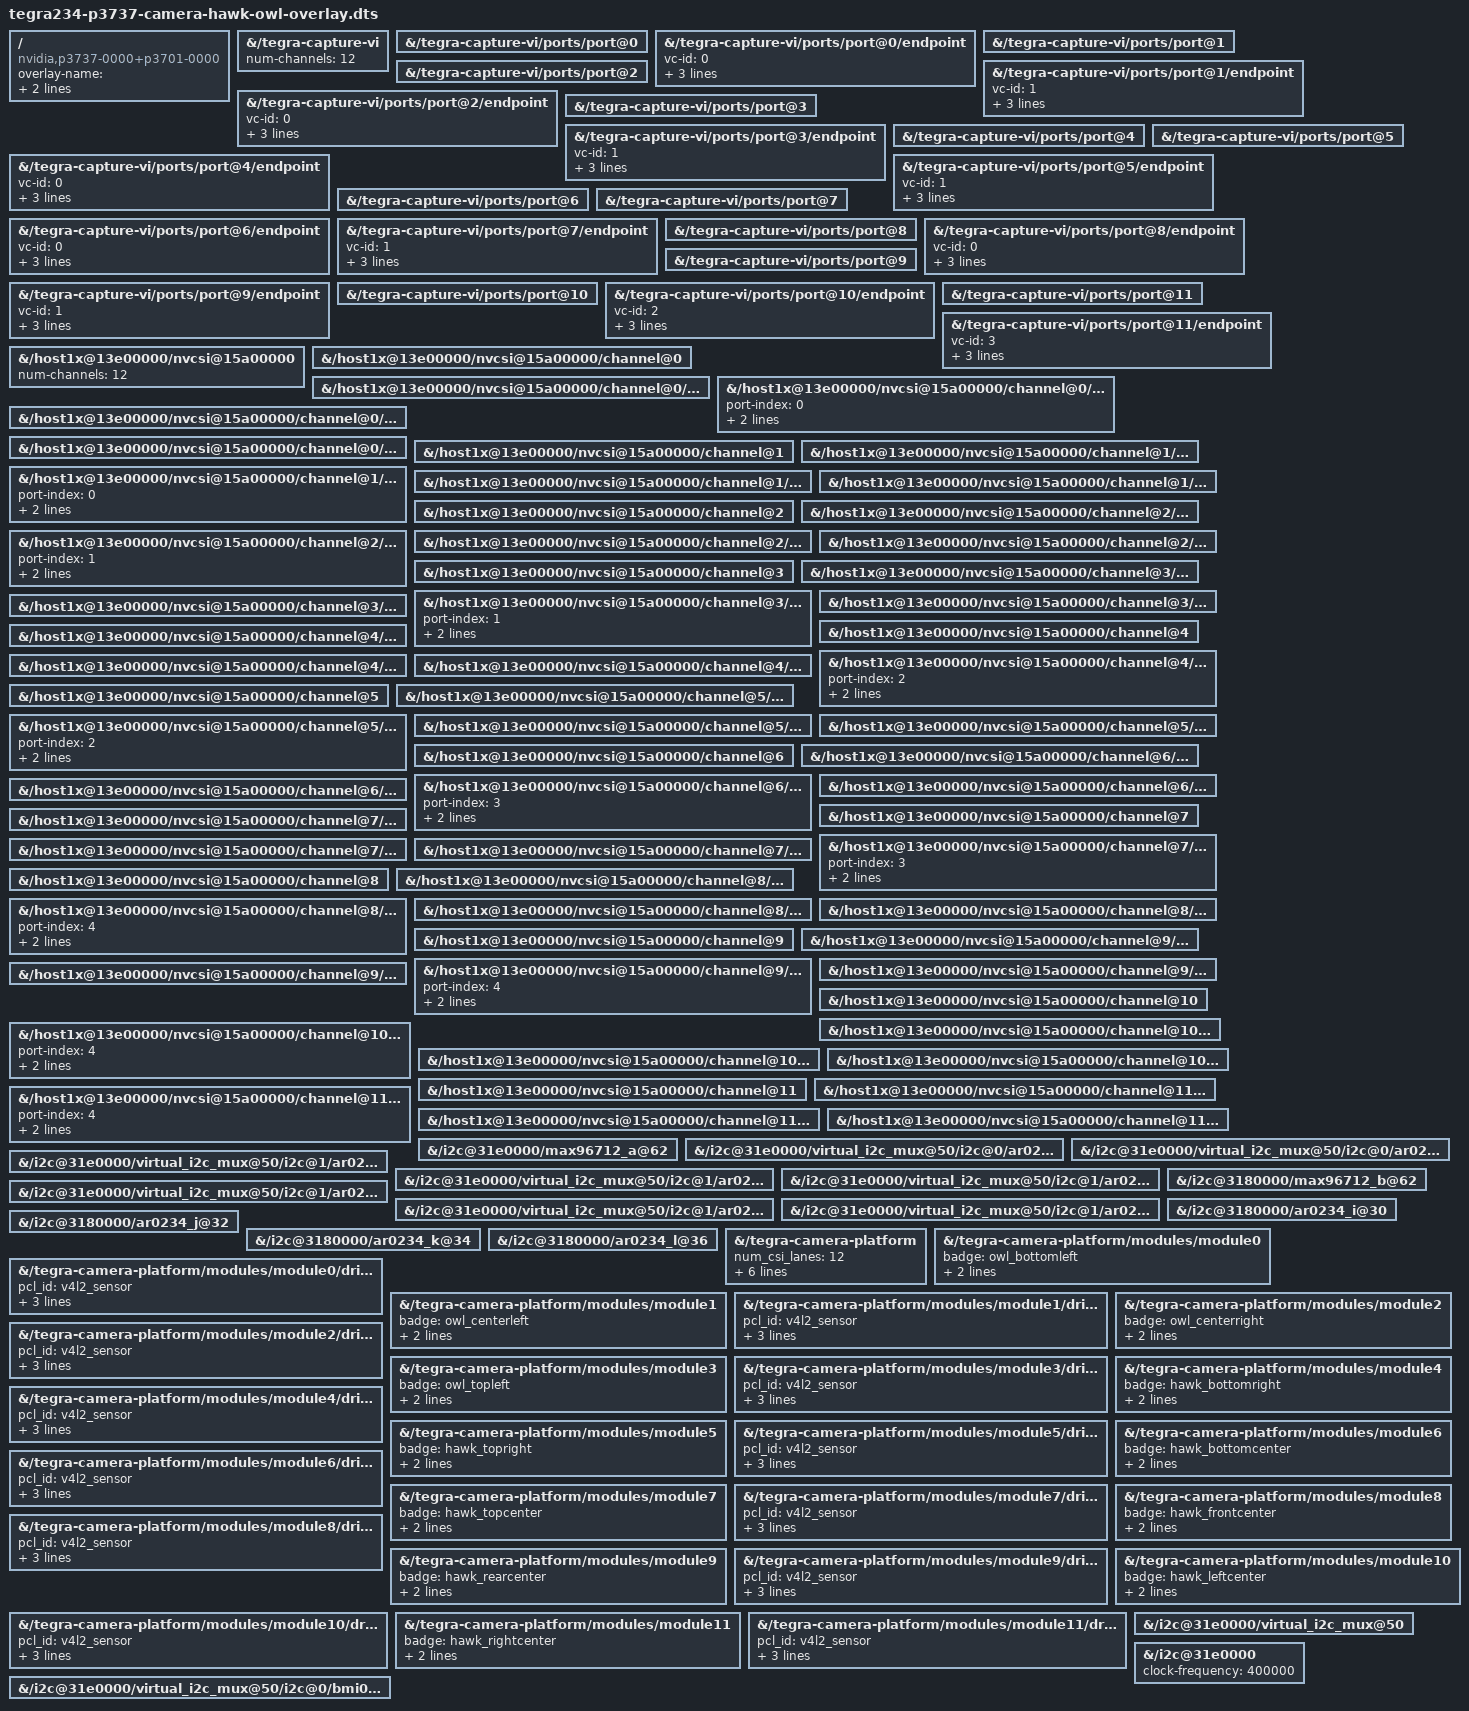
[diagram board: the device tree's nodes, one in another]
// SPDX-License-Identifier: GPL-2.0-only
/*
 * Jetson Device-tree overlay for Camera Hawk & Owl on t23x platforms
 *
 * Copyright (c) 2022-2023 NVIDIA CORPORATION. All rights reserved.
 *
 */


/dts-v1/;
/plugin/;

/ {
	overlay-name = "Jetson Camera Hawk-Owl p3762 module";
	jetson-header-name = "Jetson AGX CSI Connector";
	compatible = "nvidia,p3737-0000+p3701-0000" , "nvidia,p3737-0000+p3701-0004", "nvidia,p3737-0000+p3701-0005", "nvidia,p3737-0000+p3701-0008";

	/* VI number of channels */
	fragment@0 {
		target-path = "/tegra-capture-vi";
		board_config {
			sw-modules = "kernel";
		};
		__overlay__ {
			num-channels=<12>;
		};
	};

	fragment@1 {
		target-path = "/tegra-capture-vi/ports/port@0";
		board_config {
			sw-modules = "kernel";
		};
		__overlay__ {
			status = "okay";
		};
	};
	fragment@2 {
		target-path = "/tegra-capture-vi/ports/port@0/endpoint";
		board_config {
			sw-modules = "kernel";
		};
		__overlay__ {
			status = "okay";
			vc-id = <0>;
			port-index = <0>;
			bus-width = <2>;
			remote-endpoint = <&ar0234_csi_out0>;
		};
	};
	fragment@3 {
		target-path = "/tegra-capture-vi/ports/port@1";
		board_config {
			sw-modules = "kernel";
		};
		__overlay__ {
			status = "okay";
		};
	};
	fragment@4 {
		target-path = "/tegra-capture-vi/ports/port@1/endpoint";
		board_config {
			sw-modules = "kernel";
		};
		__overlay__ {
			status = "okay";
			vc-id = <1>;
			port-index = <0>;
			bus-width = <2>;
			remote-endpoint = <&ar0234_csi_out1>;
		};
	};
	fragment@5 {
		target-path = "/tegra-capture-vi/ports/port@2";
		board_config {
			sw-modules = "kernel";
		};
		__overlay__ {
			status = "okay";
		};
	};
	fragment@6 {
		target-path = "/tegra-capture-vi/ports/port@2/endpoint";
		board_config {
			sw-modules = "kernel";
		};
		__overlay__ {
			status = "okay";
			vc-id = <0>;
			port-index = <1>;
			bus-width = <2>;
			remote-endpoint = <&ar0234_csi_out2>;
		};
	};
	fragment@7 {
		target-path = "/tegra-capture-vi/ports/port@3";
		board_config {
			sw-modules = "kernel";
		};
		__overlay__ {
			status = "okay";
		};
	};
	fragment@8 {
		target-path = "/tegra-capture-vi/ports/port@3/endpoint";
		board_config {
			sw-modules = "kernel";
		};
		__overlay__ {
			status = "okay";
			vc-id = <1>;
			port-index = <1>;
			bus-width = <2>;
			remote-endpoint = <&ar0234_csi_out3>;
		};
	};
	fragment@9 {
		target-path = "/tegra-capture-vi/ports/port@4";
		board_config {
			sw-modules = "kernel";
		};
		__overlay__ {
			status = "okay";
		};
	};
	fragment@10 {
		target-path = "/tegra-capture-vi/ports/port@4/endpoint";
		board_config {
			sw-modules = "kernel";
		};
		__overlay__ {
			status = "okay";
			vc-id = <0>;
			port-index = <2>;
			bus-width = <2>;
			remote-endpoint = <&ar0234_csi_out4>;
		};
	};
	fragment@11 {
		target-path = "/tegra-capture-vi/ports/port@5";
		board_config {
			sw-modules = "kernel";
		};
		__overlay__ {
			status = "okay";
		};
	};
	fragment@12 {
		target-path = "/tegra-capture-vi/ports/port@5/endpoint";
		board_config {
			sw-modules = "kernel";
		};
		__overlay__ {
			status = "okay";
			vc-id = <1>;
			port-index = <2>;
			bus-width = <2>;
			remote-endpoint = <&ar0234_csi_out5>;
		};
	};
	fragment@13 {
		target-path = "/tegra-capture-vi/ports/port@6";
		board_config {
			sw-modules = "kernel";
		};
		__overlay__ {
			status = "okay";
		};
	};
	fragment@14 {
		target-path = "/tegra-capture-vi/ports/port@6/endpoint";
		board_config {
			sw-modules = "kernel";
		};
		__overlay__ {
			status = "okay";
			vc-id = <0>;
			port-index = <3>;
			bus-width = <2>;
			remote-endpoint = <&ar0234_csi_out6>;
		};
	};
	fragment@15 {
		target-path = "/tegra-capture-vi/ports/port@7";
		board_config {
			sw-modules = "kernel";
		};
		__overlay__ {
			status = "okay";
		};
	};
	fragment@16 {
		target-path = "/tegra-capture-vi/ports/port@7/endpoint";
		board_config {
			sw-modules = "kernel";
		};
		__overlay__ {
			status = "okay";
			vc-id = <1>;
			port-index = <3>;
			bus-width = <2>;
			remote-endpoint = <&ar0234_csi_out7>;
		};
	};

	fragment@17 {
		target-path = "/tegra-capture-vi/ports/port@8";
		board_config {
			sw-modules = "kernel";
		};
		__overlay__ {
			status = "okay";
		};
	};
	fragment@18 {
		target-path = "/tegra-capture-vi/ports/port@8/endpoint";
		board_config {
			sw-modules = "kernel";
		};
		__overlay__ {
			status = "okay";
			vc-id = <0>;
			port-index = <4>;
			bus-width = <2>;
			remote-endpoint = <&ar0234_csi_out8>;
		};
	};
	fragment@19 {
		target-path = "/tegra-capture-vi/ports/port@9";
		board_config {
			sw-modules = "kernel";
		};
		__overlay__ {
			status = "okay";
		};
	};
	fragment@20 {
		target-path = "/tegra-capture-vi/ports/port@9/endpoint";
		board_config {
			sw-modules = "kernel";
		};
		__overlay__ {
			status = "okay";
			vc-id = <1>;
			port-index = <4>;
			bus-width = <2>;
			remote-endpoint = <&ar0234_csi_out9>;
		};
	};
	fragment@21 {
		target-path = "/tegra-capture-vi/ports/port@10";
		board_config {
			sw-modules = "kernel";
		};
		__overlay__ {
			status = "okay";
		};
	};
	fragment@22 {
		target-path = "/tegra-capture-vi/ports/port@10/endpoint";
		board_config {
			sw-modules = "kernel";
		};
		__overlay__ {
			status = "okay";
			vc-id = <2>;
			port-index = <4>;
			bus-width = <2>;
			remote-endpoint = <&ar0234_csi_out10>;
		};
	};
	fragment@23 {
		target-path = "/tegra-capture-vi/ports/port@11";
		board_config {
			sw-modules = "kernel";
		};
		__overlay__ {
			status = "okay";
		};
	};
	fragment@24 {
		target-path = "/tegra-capture-vi/ports/port@11/endpoint";
		board_config {
			sw-modules = "kernel";
		};
		__overlay__ {
			status = "okay";
			vc-id = <3>;
			port-index = <4>;
			bus-width = <2>;
			remote-endpoint = <&ar0234_csi_out11>;
		};
	};
	/* HOST1X */
	fragment@25 {
		target-path = "/host1x@13e00000/nvcsi@15a00000";
		board_config {
			sw-modules = "kernel";
		};
		__overlay__ {
			num-channels=<12>;
		};
	};
	fragment@26 {
		target-path = "/host1x@13e00000/nvcsi@15a00000/channel@0";
		board_config {
			sw-modules = "kernel";
		};
		__overlay__ {
			status = "okay";
		};
	};
	fragment@27 {
		target-path = "/host1x@13e00000/nvcsi@15a00000/channel@0/ports/port@0";
		board_config {
			sw-modules = "kernel";
		};
		__overlay__ {
			status = "okay";
		};
	};
	fragment@28 {
		target-path = "/host1x@13e00000/nvcsi@15a00000/channel@0/ports/port@0/endpoint@0";
		board_config {
			sw-modules = "kernel";
		};
		__overlay__ {
			status = "okay";
			port-index = <0>;
			bus-width = <2>;
			remote-endpoint = <&ar0234_ar0234_out0>;
		};
	};
	fragment@29 {
		target-path = "/host1x@13e00000/nvcsi@15a00000/channel@0/ports/port@1";
		board_config {
			sw-modules = "kernel";
		};
		__overlay__ {
			status = "okay";
		};
	};
	fragment@30 {
		target-path = "/host1x@13e00000/nvcsi@15a00000/channel@0/ports/port@1/endpoint@1";
		board_config {
			sw-modules = "kernel";
		};
		__overlay__ {
			status = "okay";
		};
	};
	fragment@31 {
		target-path = "/host1x@13e00000/nvcsi@15a00000/channel@1";
		board_config {
			sw-modules = "kernel";
		};
		__overlay__ {
			status = "okay";
		};
	};
	fragment@32 {
		target-path = "/host1x@13e00000/nvcsi@15a00000/channel@1/ports/port@0";
		board_config {
			sw-modules = "kernel";
		};
		__overlay__ {
			status = "okay";
		};
	};
	fragment@33 {
		target-path = "/host1x@13e00000/nvcsi@15a00000/channel@1/ports/port@0/endpoint@2";
		board_config {
			sw-modules = "kernel";
		};
		__overlay__ {
			status = "okay";
			port-index = <0>;
			bus-width = <2>;
			remote-endpoint = <&ar0234_ar0234_out1>;
		};
	};
	fragment@34 {
		target-path = "/host1x@13e00000/nvcsi@15a00000/channel@1/ports/port@1";
		board_config {
			sw-modules = "kernel";
		};
		__overlay__ {
			status = "okay";
		};
	};
	fragment@35 {
		target-path = "/host1x@13e00000/nvcsi@15a00000/channel@1/ports/port@1/endpoint@3";
		board_config {
			sw-modules = "kernel";
		};
		__overlay__ {
			status = "okay";
		};
	};

	fragment@36 {
		target-path = "/host1x@13e00000/nvcsi@15a00000/channel@2";
		board_config {
			sw-modules = "kernel";
		};
		__overlay__ {
			status = "okay";
		};
	};
	fragment@37 {
		target-path = "/host1x@13e00000/nvcsi@15a00000/channel@2/ports/port@0";
		board_config {
			sw-modules = "kernel";
		};
		__overlay__ {
			status = "okay";
		};
	};
	fragment@38 {
		target-path = "/host1x@13e00000/nvcsi@15a00000/channel@2/ports/port@0/endpoint@4";
		board_config {
			sw-modules = "kernel";
		};
		__overlay__ {
			status = "okay";
			port-index = <1>;
			bus-width = <2>;
			remote-endpoint = <&ar0234_ar0234_out2>;
		};
	};
	fragment@39 {
		target-path = "/host1x@13e00000/nvcsi@15a00000/channel@2/ports/port@1";
		board_config {
			sw-modules = "kernel";
		};
		__overlay__ {
			status = "okay";
		};
	};
	fragment@40 {
		target-path = "/host1x@13e00000/nvcsi@15a00000/channel@2/ports/port@1/endpoint@5";
		board_config {
			sw-modules = "kernel";
		};
		__overlay__ {
			status = "okay";
		};
	};


	fragment@41 {
		target-path = "/host1x@13e00000/nvcsi@15a00000/channel@3";
		board_config {
			sw-modules = "kernel";
		};
		__overlay__ {
			status = "okay";
		};
	};
	fragment@42 {
		target-path = "/host1x@13e00000/nvcsi@15a00000/channel@3/ports/port@0";
		board_config {
			sw-modules = "kernel";
		};
		__overlay__ {
			status = "okay";
		};
	};
	fragment@43 {
		target-path = "/host1x@13e00000/nvcsi@15a00000/channel@3/ports/port@0/endpoint@6";
		board_config {
			sw-modules = "kernel";
		};
		__overlay__ {
			status = "okay";
			port-index = <1>;
			bus-width = <2>;
			remote-endpoint = <&ar0234_ar0234_out3>;
		};
	};
	fragment@44 {
		target-path = "/host1x@13e00000/nvcsi@15a00000/channel@3/ports/port@1";
		board_config {
			sw-modules = "kernel";
		};
		__overlay__ {
			status = "okay";
		};
	};
	fragment@45 {
		target-path = "/host1x@13e00000/nvcsi@15a00000/channel@3/ports/port@1/endpoint@7";
		board_config {
			sw-modules = "kernel";
		};
		__overlay__ {
			status = "okay";
		};
	};


	fragment@46 {
		target-path = "/host1x@13e00000/nvcsi@15a00000/channel@4";
		board_config {
			sw-modules = "kernel";
		};
		__overlay__ {
			status = "okay";
		};
	};
	fragment@47 {
		target-path = "/host1x@13e00000/nvcsi@15a00000/channel@4/ports/port@0";
		board_config {
			sw-modules = "kernel";
		};
		__overlay__ {
			status = "okay";
		};
	};
	fragment@48 {
		target-path = "/host1x@13e00000/nvcsi@15a00000/channel@4/ports/port@0/endpoint@8";
		board_config {
			sw-modules = "kernel";
		};
		__overlay__ {
			status = "okay";
			port-index = <2>;
			bus-width = <2>;
			remote-endpoint = <&ar0234_ar0234_out4>;
		};
	};
	fragment@49 {
		target-path = "/host1x@13e00000/nvcsi@15a00000/channel@4/ports/port@1";
		board_config {
			sw-modules = "kernel";
		};
		__overlay__ {
			status = "okay";
		};
	};
	fragment@50 {
		target-path = "/host1x@13e00000/nvcsi@15a00000/channel@4/ports/port@1/endpoint@9";
		board_config {
			sw-modules = "kernel";
		};
		__overlay__ {
			status = "okay";
		};
	};


	fragment@51 {
		target-path = "/host1x@13e00000/nvcsi@15a00000/channel@5";
		board_config {
			sw-modules = "kernel";
		};
		__overlay__ {
			status = "okay";
		};
	};
	fragment@52 {
		target-path = "/host1x@13e00000/nvcsi@15a00000/channel@5/ports/port@0";
		board_config {
			sw-modules = "kernel";
		};
		__overlay__ {
			status = "okay";
		};
	};
	fragment@53 {
		target-path = "/host1x@13e00000/nvcsi@15a00000/channel@5/ports/port@0/endpoint@10";
		board_config {
			sw-modules = "kernel";
		};
		__overlay__ {
			status = "okay";
			port-index = <2>;
			bus-width = <2>;
			remote-endpoint = <&ar0234_ar0234_out5>;
		};
	};
	fragment@54 {
		target-path = "/host1x@13e00000/nvcsi@15a00000/channel@5/ports/port@1";
		board_config {
			sw-modules = "kernel";
		};
		__overlay__ {
			status = "okay";
		};
	};
	fragment@55 {
		target-path = "/host1x@13e00000/nvcsi@15a00000/channel@5/ports/port@1/endpoint@11";
		board_config {
			sw-modules = "kernel";
		};
		__overlay__ {
			status = "okay";
		};
	};

	fragment@56 {
		target-path = "/host1x@13e00000/nvcsi@15a00000/channel@6";
		board_config {
			sw-modules = "kernel";
		};
		__overlay__ {
			status = "okay";
		};
	};
	fragment@57 {
		target-path = "/host1x@13e00000/nvcsi@15a00000/channel@6/ports/port@0";
		board_config {
			sw-modules = "kernel";
		};
		__overlay__ {
			status = "okay";
		};
	};
	fragment@58 {
		target-path = "/host1x@13e00000/nvcsi@15a00000/channel@6/ports/port@0/endpoint@12";
		board_config {
			sw-modules = "kernel";
		};
		__overlay__ {
			status = "okay";
			port-index = <3>;
			bus-width = <2>;
			remote-endpoint = <&ar0234_ar0234_out6>;
		};
	};
	fragment@59 {
		target-path = "/host1x@13e00000/nvcsi@15a00000/channel@6/ports/port@1";
		board_config {
			sw-modules = "kernel";
		};
		__overlay__ {
			status = "okay";
		};
	};
	fragment@60 {
		target-path = "/host1x@13e00000/nvcsi@15a00000/channel@6/ports/port@1/endpoint@13";
		board_config {
			sw-modules = "kernel";
		};
		__overlay__ {
			status = "okay";
		};
	};


	fragment@61 {
		target-path = "/host1x@13e00000/nvcsi@15a00000/channel@7";
		board_config {
			sw-modules = "kernel";
		};
		__overlay__ {
			status = "okay";
		};
	};
	fragment@62 {
		target-path = "/host1x@13e00000/nvcsi@15a00000/channel@7/ports/port@0";
		board_config {
			sw-modules = "kernel";
		};
		__overlay__ {
			status = "okay";
		};
	};
	fragment@63 {
		target-path = "/host1x@13e00000/nvcsi@15a00000/channel@7/ports/port@0/endpoint@14";
		board_config {
			sw-modules = "kernel";
		};
		__overlay__ {
			status = "okay";
			port-index = <3>;
			bus-width = <2>;
			remote-endpoint = <&ar0234_ar0234_out7>;
		};
	};
	fragment@64 {
		target-path = "/host1x@13e00000/nvcsi@15a00000/channel@7/ports/port@1";
		board_config {
			sw-modules = "kernel";
		};
		__overlay__ {
			status = "okay";
		};
	};
	fragment@65 {
		target-path = "/host1x@13e00000/nvcsi@15a00000/channel@7/ports/port@1/endpoint@15";
		board_config {
			sw-modules = "kernel";
		};
		__overlay__ {
			status = "okay";
		};
	};
	fragment@66 {
		target-path = "/host1x@13e00000/nvcsi@15a00000/channel@8";
		board_config {
			sw-modules = "kernel";
		};
		__overlay__ {
			status = "okay";
		};
	};
	fragment@67 {
		target-path = "/host1x@13e00000/nvcsi@15a00000/channel@8/ports/port@0";
		board_config {
			sw-modules = "kernel";
		};
		__overlay__ {
			status = "okay";
		};
	};
	fragment@68 {
		target-path = "/host1x@13e00000/nvcsi@15a00000/channel@8/ports/port@0/endpoint@16";
		board_config {
			sw-modules = "kernel";
		};
		__overlay__ {
			status = "okay";
			port-index = <4>;
			bus-width = <2>;
			remote-endpoint = <&ar0234_ar0234_out8>;
		};
	};
	fragment@69 {
		target-path = "/host1x@13e00000/nvcsi@15a00000/channel@8/ports/port@1";
		board_config {
			sw-modules = "kernel";
		};
		__overlay__ {
			status = "okay";
		};
	};
	fragment@70 {
		target-path = "/host1x@13e00000/nvcsi@15a00000/channel@8/ports/port@1/endpoint@17";
		board_config {
			sw-modules = "kernel";
		};
		__overlay__ {
			status = "okay";
		};
	};
	fragment@71 {
		target-path = "/host1x@13e00000/nvcsi@15a00000/channel@9";
		board_config {
			sw-modules = "kernel";
		};
		__overlay__ {
			status = "okay";
		};
	};
	fragment@72 {
		target-path = "/host1x@13e00000/nvcsi@15a00000/channel@9/ports/port@0";
		board_config {
			sw-modules = "kernel";
		};
		__overlay__ {
			status = "okay";
		};
	};
	fragment@73 {
		target-path = "/host1x@13e00000/nvcsi@15a00000/channel@9/ports/port@0/endpoint@18";
		board_config {
			sw-modules = "kernel";
		};
		__overlay__ {
			status = "okay";
			port-index = <4>;
			bus-width = <2>;
			remote-endpoint = <&ar0234_ar0234_out9>;
		};
	};
	fragment@74 {
		target-path = "/host1x@13e00000/nvcsi@15a00000/channel@9/ports/port@1";
		board_config {
			sw-modules = "kernel";
		};
		__overlay__ {
			status = "okay";
		};
	};
	fragment@75 {
		target-path = "/host1x@13e00000/nvcsi@15a00000/channel@9/ports/port@1/endpoint@19";
		board_config {
			sw-modules = "kernel";
		};
		__overlay__ {
			status = "okay";
		};
	};
	fragment@76 {
		target-path = "/host1x@13e00000/nvcsi@15a00000/channel@10";
		board_config {
			sw-modules = "kernel";
		};
		__overlay__ {
			status = "okay";
		};
	};
	fragment@77 {
		target-path = "/host1x@13e00000/nvcsi@15a00000/channel@10/ports/port@0";
		board_config {
			sw-modules = "kernel";
		};
		__overlay__ {
		status = "okay";
		};
	};
	fragment@78 {
		target-path = "/host1x@13e00000/nvcsi@15a00000/channel@10/ports/port@0/endpoint@20";
		board_config {
			sw-modules = "kernel";
		};
		__overlay__ {
			status = "okay";
			port-index = <4>;
			bus-width = <2>;
			remote-endpoint = <&ar0234_ar0234_out10>;
		};
	};
	fragment@79 {
		target-path = "/host1x@13e00000/nvcsi@15a00000/channel@10/ports/port@1";
		board_config {
			sw-modules = "kernel";
		};
		__overlay__ {
			status = "okay";
		};
	};
	fragment@80 {
		target-path = "/host1x@13e00000/nvcsi@15a00000/channel@10/ports/port@1/endpoint@21";
		board_config {
			sw-modules = "kernel";
		};
		__overlay__ {
			status = "okay";
		};
	};
	fragment@81 {
		target-path = "/host1x@13e00000/nvcsi@15a00000/channel@11";
		board_config {
			sw-modules = "kernel";
		};
		__overlay__ {
			status = "okay";
		};
	};
	fragment@82 {
		target-path = "/host1x@13e00000/nvcsi@15a00000/channel@11/ports/port@0";
		board_config {
			sw-modules = "kernel";
		};
		__overlay__ {
		status = "okay";
		};
	};
	fragment@83 {
		target-path = "/host1x@13e00000/nvcsi@15a00000/channel@11/ports/port@0/endpoint@22";
		board_config {
			sw-modules = "kernel";
		};
		__overlay__ {
			status = "okay";
			port-index = <4>;
			bus-width = <2>;
			remote-endpoint = <&ar0234_ar0234_out11>;
		};
	};
	fragment@84 {
		target-path = "/host1x@13e00000/nvcsi@15a00000/channel@11/ports/port@1";
		board_config {
			sw-modules = "kernel";
		};
		__overlay__ {
			status = "okay";
		};
	};
	fragment@85 {
		target-path = "/host1x@13e00000/nvcsi@15a00000/channel@11/ports/port@1/endpoint@23";
		board_config {
			sw-modules = "kernel";
		};
		__overlay__ {
			status = "okay";
		};
	};
	/* End of Host1X */

        fragment@86 {
                target-path = "/i2c@31e0000/max96712_a@62";
                board_config {
                        sw-modules = "kernel";
                };
                __overlay__ {
                        status = "okay";
                };
        };

	fragment@87 {
		target-path = "/i2c@31e0000/virtual_i2c_mux@50/i2c@0/ar0234_a@30";
		board_config {
			sw-modules = "kernel";
		};
		__overlay__ {
			status = "okay";
		};
	};
	fragment@88 {
		target-path = "/i2c@31e0000/virtual_i2c_mux@50/i2c@0/ar0234_b@31";
		board_config {
			sw-modules = "kernel";
		};
		__overlay__ {
			status = "okay";
		};
	};
	fragment@89 {
		target-path = "/i2c@31e0000/virtual_i2c_mux@50/i2c@1/ar0234_c@32";
		board_config {
			sw-modules = "kernel";
		};
		__overlay__ {
			status = "okay";
		};
	};
	fragment@90 {
		target-path = "/i2c@31e0000/virtual_i2c_mux@50/i2c@1/ar0234_d@33";
		board_config {
			sw-modules = "kernel";
		};
		__overlay__ {
			status = "okay";
		};
	};
	fragment@91 {
		target-path = "/i2c@31e0000/virtual_i2c_mux@50/i2c@1/ar0234_e@34";
		board_config {
			sw-modules = "kernel";
		};
		__overlay__ {
			status = "okay";
		};
	};
	fragment@92 {
		target-path = "/i2c@31e0000/virtual_i2c_mux@50/i2c@1/ar0234_f@35";
		board_config {
			sw-modules = "kernel";
		};
		__overlay__ {
			status = "okay";
		};
	};

	fragment@93 {
		target-path = "/i2c@31e0000/virtual_i2c_mux@50/i2c@1/ar0234_g@36";
		board_config {
			sw-modules = "kernel";
		};
		__overlay__ {
			status = "okay";
		};
	};
	fragment@94 {
		target-path = "/i2c@31e0000/virtual_i2c_mux@50/i2c@1/ar0234_h@37";
		board_config {
			sw-modules = "kernel";
		};
		__overlay__ {
			status = "okay";
		};
	};
	/* Owl sensors */
       fragment@95 {
                target-path = "/i2c@3180000/max96712_b@62";
                board_config {
                        sw-modules = "kernel";
                };
                __overlay__ {
                        status = "okay";
                };
        };
	fragment@96 {
		target-path = "/i2c@3180000/ar0234_i@30";
		board_config {
			sw-modules = "kernel";
		};
		__overlay__ {
			status = "okay";
		};
	};
	fragment@97 {
		target-path = "/i2c@3180000/ar0234_j@32";
		board_config {
			sw-modules = "kernel";
		};
		__overlay__ {
			status = "okay";
		};
	};
	fragment@98 {
		target-path = "/i2c@3180000/ar0234_k@34";
		board_config {
			sw-modules = "kernel";
		};
		__overlay__ {
			status = "okay";
		};
	};
	fragment@99 {
		target-path = "/i2c@3180000/ar0234_l@36";
		board_config {
			sw-modules = "kernel";
		};
		__overlay__ {
			status = "okay";
		};
	};

	fragment@100 {
		target-path = "/tegra-camera-platform";
		board_config {
			sw-modules = "kernel";
		};
		__overlay__ {
			num_csi_lanes = <12>;
			max_lane_speed = <1500000>;
			min_bits_per_pixel = <10>;
			vi_peak_byte_per_pixel = <2>;
			vi_bw_margin_pct = <25>;
			isp_peak_byte_per_pixel = <5>;
			isp_bw_margin_pct = <25>;
		};
	};

	fragment@101 {
		target-path = "/tegra-camera-platform/modules/module0";
		board_config {
			sw-modules = "kernel";
		};
		__overlay__ {
			status = "okay";
			badge = "owl_bottomleft";
			position = "bottomleft";
			orientation = "1";
		};
	};

	fragment@102 {
		target-path = "/tegra-camera-platform/modules/module0/drivernode0";
		board_config {
			sw-modules = "kernel";
		};
		__overlay__ {
			status = "okay";
			pcl_id = "v4l2_sensor";
			devname = "ar0234 2-0030";
			proc-device-tree = "/proc/device-tree/i2c@3180000/ar0234_i@30";
		};
	};

	fragment@103 {
		target-path = "/tegra-camera-platform/modules/module1";
		board_config {
			sw-modules = "kernel";
		};
		__overlay__ {
			status = "okay";
			badge = "owl_centerleft";
			position = "centerleft";
			orientation = "1";
		};
	};

	fragment@104 {
		target-path = "/tegra-camera-platform/modules/module1/drivernode0";
		board_config {
			sw-modules = "kernel";
		};
		__overlay__ {
			status = "okay";
			pcl_id = "v4l2_sensor";
			devname = "ar0234 2-0032";
			proc-device-tree = "/proc/device-tree/i2c@3180000/ar0234_j@32";
		};
	};

	fragment@105 {
		target-path = "/tegra-camera-platform/modules/module2";
		board_config {
			sw-modules = "kernel";
		};
		__overlay__ {
			status = "okay";
			badge = "owl_centerright";
			position = "centerright";
			orientation = "1";
		};
	};

	fragment@106 {
		target-path = "/tegra-camera-platform/modules/module2/drivernode0";
		board_config {
			sw-modules = "kernel";
		};
		__overlay__ {
			status = "okay";
			pcl_id = "v4l2_sensor";
			devname = "ar0234 2-0034";
			proc-device-tree = "/proc/device-tree/i2c@3180000/ar0234_k@34";
		};
	};

	fragment@107 {
		target-path = "/tegra-camera-platform/modules/module3";
		board_config {
			sw-modules = "kernel";
		};
		__overlay__ {
			status = "okay";
			badge = "owl_topleft";
			position = "topleft";
			orientation = "1";
		};
	};

	fragment@108 {
		target-path = "/tegra-camera-platform/modules/module3/drivernode0";
		board_config {
			sw-modules = "kernel";
		};
		__overlay__ {
			status = "okay";
			pcl_id = "v4l2_sensor";
			devname = "ar0234 2-0036";
			proc-device-tree = "/proc/device-tree/i2c@3180000/ar0234_l@36";
		};
	};

	fragment@109 {
		target-path = "/tegra-camera-platform/modules/module4";
		board_config {
			sw-modules = "kernel";
		};
		__overlay__ {
			status = "okay";
			badge = "hawk_bottomright";
			position = "bottomright";
			orientation = "1";
		};
	};

	fragment@110 {
		target-path = "/tegra-camera-platform/modules/module4/drivernode0";
		board_config {
			sw-modules = "kernel";
		};
		__overlay__ {
			status = "okay";
			pcl_id = "v4l2_sensor";
			devname = "ar0234 9-0030";
			proc-device-tree = "/proc/device-tree/i2c@31e0000/virtual_i2c_mux@50/i2c@0/ar0234_a@30";
		};
	};

	fragment@111 {
		target-path = "/tegra-camera-platform/modules/module5";
		board_config {
			sw-modules = "kernel";
		};
		__overlay__ {
			status = "okay";
			badge = "hawk_topright";
			position = "topright";
			orientation = "1";
		};
	};

	fragment@112 {
		target-path = "/tegra-camera-platform/modules/module5/drivernode0";
		board_config {
			sw-modules = "kernel";
		};
		__overlay__ {
			status = "okay";
			pcl_id = "v4l2_sensor";
			devname = "ar0234 9-0031";
			proc-device-tree = "/proc/device-tree/i2c@31e0000/virtual_i2c_mux@50/i2c@0/ar0234_b@31";
		};
	};

	fragment@113 {
		target-path = "/tegra-camera-platform/modules/module6";
		board_config {
			sw-modules = "kernel";
		};
		__overlay__ {
			status = "okay";
			badge = "hawk_bottomcenter";
			position = "bottomcenter";
			orientation = "1";
		};
	};

	fragment@114 {
		target-path = "/tegra-camera-platform/modules/module6/drivernode0";
		board_config {
			sw-modules = "kernel";
		};
		__overlay__ {
			status = "okay";
			pcl_id = "v4l2_sensor";
			devname = "ar0234 10-0032";
			proc-device-tree = "/proc/device-tree/i2c@31e0000/virtual_i2c_mux@50/i2c@1/ar0234_c@32";
		};
	};

	fragment@115 {
		target-path = "/tegra-camera-platform/modules/module7";
		board_config {
			sw-modules = "kernel";
		};
		__overlay__ {
			status = "okay";
			badge = "hawk_topcenter";
			position = "topcenter";
			orientation = "1";
		};
	};

	fragment@116 {
		target-path = "/tegra-camera-platform/modules/module7/drivernode0";
		board_config {
			sw-modules = "kernel";
		};
		__overlay__ {
			status = "okay";
			pcl_id = "v4l2_sensor";
			devname = "ar0234 10-0033";
			proc-device-tree = "/proc/device-tree/i2c@31e0000/virtual_i2c_mux@50/i2c@1/ar0234_d@33";
		};
	};
	fragment@117 {
		target-path = "/tegra-camera-platform/modules/module8";
		board_config {
			sw-modules = "kernel";
		};
		__overlay__ {
			status = "okay";
			badge = "hawk_frontcenter";
			position = "frontcenter";
			orientation = "1";
		};
	};
	fragment@118 {
		target-path = "/tegra-camera-platform/modules/module8/drivernode0";
		board_config {
			sw-modules = "kernel";
		};
		__overlay__ {
			status = "okay";
			pcl_id = "v4l2_sensor";
			devname = "ar0234 10-0034";
			proc-device-tree = "/proc/device-tree/i2c@31e0000/virtual_i2c_mux@50/i2c@1/ar0234_e@34";
		};
	};
	fragment@119 {
		target-path = "/tegra-camera-platform/modules/module9";
		board_config {
			sw-modules = "kernel";
		};
		__overlay__ {
			status = "okay";
			badge = "hawk_rearcenter";
			position = "rearcenter";
			orientation = "1";
		};
	};
	fragment@120 {
		target-path = "/tegra-camera-platform/modules/module9/drivernode0";
		board_config {
			sw-modules = "kernel";
		};
		__overlay__ {
			status = "okay";
			pcl_id = "v4l2_sensor";
			devname = "ar0234 10-0035";
			proc-device-tree = "/proc/device-tree/i2c@31e0000/virtual_i2c_mux@50/i2c@1/ar0234_f@35";
		};
	};
	fragment@121 {
		target-path = "/tegra-camera-platform/modules/module10";
		board_config {
			sw-modules = "kernel";
		};
		__overlay__ {
			status = "okay";
			badge = "hawk_leftcenter";
			position = "leftcenter";
			orientation = "1";
		};
	};
	fragment@122 {
		target-path = "/tegra-camera-platform/modules/module10/drivernode0";
		board_config {
			sw-modules = "kernel";
		};
		__overlay__ {
			status = "okay";
			pcl_id = "v4l2_sensor";
			devname = "ar0234 10-0036";
			proc-device-tree = "/proc/device-tree/i2c@31e0000/virtual_i2c_mux@50/i2c@1/ar0234_g@36";
		};
	};
	fragment@123 {
		target-path = "/tegra-camera-platform/modules/module11";
		board_config {
			sw-modules = "kernel";
		};
		__overlay__ {
			status = "okay";
			badge = "hawk_rightcenter";
			position = "rightcenter";
			orientation = "1";
		};
	};
	fragment@124 {
		target-path = "/tegra-camera-platform/modules/module11/drivernode0";
		board_config {
			sw-modules = "kernel";
		};
		__overlay__ {
			status = "okay";
			pcl_id = "v4l2_sensor";
			devname = "ar0234 10-0037";
			proc-device-tree = "/proc/device-tree/i2c@31e0000/virtual_i2c_mux@50/i2c@1/ar0234_h@37";
		};
	};
	fragment@125 {
		target-path = "/i2c@31e0000/virtual_i2c_mux@50";
		board_config {
			sw-modules = "kernel";
		};
		__overlay__ {
			status = "okay";
		};
	};
	fragment@126 {
		target-path = "/i2c@31e0000/virtual_i2c_mux@50/i2c@0/bmi088_a@69";
		board_config {
			sw-modules = "kernel";
		};
		__overlay__ {
			status = "okay";
		};
	};
	fragment@127 {
		target-path = "/i2c@31e0000";
		board_config {
			sw-modules = "kernel";
		};
		__overlay__ {
			clock-frequency = <400000>;
		};
	};
};
